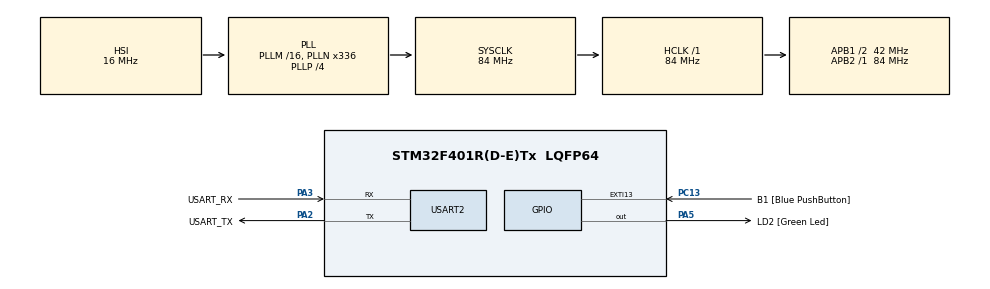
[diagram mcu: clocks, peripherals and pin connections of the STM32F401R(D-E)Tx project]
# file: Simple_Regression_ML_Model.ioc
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Mcu.Family=STM32F4
PA2.GPIO_PuPd=GPIO_NOPULL
VP_STMicroelectronics.X-CUBE-AI_VS_ArtificialOoIntelligenceJjXAaCUBEAaAI_6.0.0.Mode=ArtificialOoIntelligenceJjXAaCUBEAaAI
RCC.CortexFreq_Value=84000000
STMicroelectronics.X-CUBE-AI.6.0.0.ModelFlashOccupation-a35f5c20a5aa916bef2a292ab1ee2da6ee86460b59aac95d9a262698d66ec36b=16
STMicroelectronics.X-CUBE-AI.6.0.0.MaximumSizeOfInputLayer=AI_NETWORK_IN_1_SIZE_BYTES
PA14.GPIO_Label=TCK
VP_STMicroelectronics.X-CUBE-AI_VS_DeviceJjApplication_6.0.0.Mode=DeviceJjApplication
PA3.GPIO_PuPd=GPIO_NOPULL
PA2.GPIO_Speed=GPIO_SPEED_FREQ_LOW
STMicroelectronics.X-CUBE-AI.6.0.0.StackSize=0x1000
PA3.GPIO_Speed=GPIO_SPEED_FREQ_LOW
STMicroelectronics.X-CUBE-AI.6.0.0.ModelActualCompression-a35f5c20a5aa916bef2a292ab1ee2da6ee86460b59aac95d9a262698d66ec36b=0.0
RCC.SYSCLKSource=RCC_SYSCLKSOURCE_PLLCLK
ProjectManager.StackSize=0x1000
PH0\ -\ OSC_IN.Signal=RCC_OSC_IN
RCC.HCLKFreq_Value=84000000
RCC.APB2TimFreq_Value=84000000
RCC.AHBFreq_Value=84000000
STMicroelectronics.X-CUBE-AI.6.0.0.ModelCompression-a35f5c20a5aa916bef2a292ab1ee2da6ee86460b59aac95d9a262698d66ec36b=1
RCC.HSE_VALUE=8000000
PC13-ANTI_TAMP.Signal=GPXTI13
STMicroelectronics.X-CUBE-AI.6.0.0.XAaCUBEAaAICcArtificialOoIntelligenceJjCore=true
PA5.GPIO_PuPd=GPIO_NOPULL
NVIC.TIM2_IRQn=true\:0\:0\:false\:false\:true\:true\:true
STMicroelectronics.X-CUBE-AI.6.0.0.ModelMacc-a35f5c20a5aa916bef2a292ab1ee2da6ee86460b59aac95d9a262698d66ec36b=4
STMicroelectronics.X-CUBE-AI.6.0.0.ModelName-a35f5c20a5aa916bef2a292ab1ee2da6ee86460b59aac95d9a262698d66ec36b=network
Mcu.Package=LQFP64
TIM2.Prescaler=9999
USART2.VirtualMode=VM_ASYNC
PA2.GPIO_Label=USART_TX
RCC.APB1TimFreq_Value=84000000
STMicroelectronics.X-CUBE-AI.6.0.0.ModelStructureFile-a35f5c20a5aa916bef2a292ab1ee2da6ee86460b59aac95d9a262698d66ec36b=/Users/massimomerenda/eML/LARSEC/Regression_ML_Model/network_regression.h5
PA3.Signal=USART2_RX
STMicroelectronics.X-CUBE-AI.6.0.0.ModelRamOccupation-a35f5c20a5aa916bef2a292ab1ee2da6ee86460b59aac95d9a262698d66ec36b=16
PA2.GPIO_Mode=GPIO_MODE_AF_PP
PB3.GPIO_Label=SWO
PC13-ANTI_TAMP.GPIO_PuPd=GPIO_NOPULL
PC13-ANTI_TAMP.GPIO_Label=B1 [Blue PushButton]
STMicroelectronics.X-CUBE-AI.6.0.0.MaximumSizeOfOutputLayer=AI_NETWORK_OUT_1_SIZE_BYTES
RCC.APB1CLKDivider=RCC_HCLK_DIV2
PC14-OSC32_IN.Signal=RCC_OSC32_IN
PA3.Mode=Asynchronous
PA13.Signal=SYS_JTMS-SWDIO
STMicroelectronics.X-CUBE-AI.6.0.0.ModelHashList=a35f5c20a5aa916bef2a292ab1ee2da6ee86460b59aac95d9a262698d66ec36b
ProjectManager.TargetToolchain=STM32CubeIDE
STMicroelectronics.X-CUBE-AI.6.0.0.InternalRamActivationBufferMaxSize=AI_NETWORK_DATA_ACTIVATIONS_SIZE
PA3.GPIO_Mode=GPIO_MODE_AF_PP
STMicroelectronics.X-CUBE-AI.6.0.0.WorkingBufferStartAddrList=0xFFFFFFFF
STMicroelectronics.X-CUBE-AI.6.0.0.ModelNameList=network
STMicroelectronics.X-CUBE-AI.6.0.0.MaximumNumberOfOutputLayer=1
RCC.LSE_VALUE=32768
PC15-OSC32_OUT.Signal=RCC_OSC32_OUT
STMicroelectronics.X-CUBE-AI.6.0.0.LatestDirectoryUsed-a35f5c20a5aa916bef2a292ab1ee2da6ee86460b59aac95d9a262698d66ec36b=/Users/massimomerenda/eML/LARSEC/Regression_ML_Model
PA5.Signal=GPIO_Output
PH1\ -\ OSC_OUT.Signal=RCC_OSC_OUT
board=NUCLEO-F401RE
RCC.VCOOutputFreq_Value=336000000
RCC.APB2Freq_Value=84000000
VP_TIM2_VS_ClockSourceINT.Mode=Internal
STMicroelectronics.X-CUBE-AI.6.0.0.ModelKind-a35f5c20a5aa916bef2a292ab1ee2da6ee86460b59aac95d9a262698d66ec36b=KERAS
TIM2.Period=8399
STMicroelectronics.X-CUBE-AI.6.0.0.ApplicationCcDeviceJjApplication=ApplicationTemplate
Mcu.Name=STM32F401R(D-E)Tx
PA13.GPIO_Label=TMS
PA2.Signal=USART2_TX
PB3.Signal=SYS_JTDO-SWO
RCC.SYSCLKFreq_VALUE=84000000
PA5.GPIO_Label=LD2 [Green Led]
PC13-ANTI_TAMP.GPIO_ModeDefaultEXTI=GPIO_MODE_IT_FALLING
PA14.Signal=SYS_JTCK-SWCLK
STMicroelectronics.X-CUBE-AI.6.0.0.MaximumNumberOfInputLayer=1
ProjectManager.HeapSize=0x200
STMicroelectronics.X-CUBE-AI.6.0.0.HeapSize=0x200
RCC.HSI_VALUE=16000000
RCC.PLLP=RCC_PLLP_DIV4
PA5.GPIO_Speed=GPIO_SPEED_FREQ_LOW
RCC.PLLQ=7
NVIC.PriorityGroup=NVIC_PRIORITYGROUP_0
RCC.PLLN=336
PA2.Mode=Asynchronous
STMicroelectronics.X-CUBE-AI.6.0.0.ModelType-a35f5c20a5aa916bef2a292ab1ee2da6ee86460b59aac95d9a262698d66ec36b=Saved model
RCC.APB1Freq_Value=42000000
PA5.GPIO_Mode=GPIO_MODE_OUTPUT_PP
VP_CRC_VS_CRC.Mode=CRC_Activate
STMicroelectronics.X-CUBE-AI.6.0.0.ActivationBufferSizeList=16
PA3.GPIO_Label=USART_RX

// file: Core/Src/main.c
/* USER CODE BEGIN Header */
/**
  ******************************************************************************
  * @file           : main.c
  * @brief          : Main program body
  ******************************************************************************
  * @attention
  *
  * <h2><center>&copy; Copyright (c) 2021 STMicroelectronics.
  * All rights reserved.</center></h2>
  *
  * This software component is licensed by ST under BSD 3-Clause license,
  * the "License"; You may not use this file except in compliance with the
  * License. You may obtain a copy of the License at:
  *                        opensource.org/licenses/BSD-3-Clause
  *
  ******************************************************************************
  */
/* USER CODE END Header */
#include "main.h"
#include "app_x-cube-ai.h"

CRC_HandleTypeDef hcrc;

TIM_HandleTypeDef htim2;

UART_HandleTypeDef huart2;

void SystemClock_Config(void);
static void MX_GPIO_Init(void);
static void MX_CRC_Init(void);
static void MX_USART2_UART_Init(void);
static void MX_TIM2_Init(void);

int main(void)
{

  /* MCU Configuration--------------------------------------------------------*/

  /* Reset of all peripherals, Initializes the Flash interface and the Systick. */
  HAL_Init();

  /* Configure the system clock */
  SystemClock_Config();

  /* Initialize all configured peripherals */
  MX_GPIO_Init();
  MX_CRC_Init();
  MX_USART2_UART_Init();
  MX_TIM2_Init();
  MX_X_CUBE_AI_Init();
  /* USER CODE BEGIN 2 */

  HAL_TIM_Base_Start_IT(&htim2); // Timer 2 start command
  /* USER CODE END 2 */

  /* Infinite loop */
  while (1)
  {

  //MX_X_CUBE_AI_Process();
  }
}

void SystemClock_Config(void)
{
  RCC_OscInitTypeDef RCC_OscInitStruct = {0};
  RCC_ClkInitTypeDef RCC_ClkInitStruct = {0};

  /** Configure the main internal regulator output voltage
  */
  __HAL_RCC_PWR_CLK_ENABLE();
  __HAL_PWR_VOLTAGESCALING_CONFIG(PWR_REGULATOR_VOLTAGE_SCALE2);
  /** Initializes the RCC Oscillators according to the specified parameters
  * in the RCC_OscInitTypeDef structure.
  */
  RCC_OscInitStruct.OscillatorType = RCC_OSCILLATORTYPE_HSI;
  RCC_OscInitStruct.HSIState = RCC_HSI_ON;
  RCC_OscInitStruct.HSICalibrationValue = RCC_HSICALIBRATION_DEFAULT;
  RCC_OscInitStruct.PLL.PLLState = RCC_PLL_ON;
  RCC_OscInitStruct.PLL.PLLSource = RCC_PLLSOURCE_HSI;
  RCC_OscInitStruct.PLL.PLLM = 16;
  RCC_OscInitStruct.PLL.PLLN = 336;
  RCC_OscInitStruct.PLL.PLLP = RCC_PLLP_DIV4;
  RCC_OscInitStruct.PLL.PLLQ = 7;
  if (HAL_RCC_OscConfig(&RCC_OscInitStruct) != HAL_OK)
  {
    Error_Handler();
  }
  /** Initializes the CPU, AHB and APB buses clocks
  */
  RCC_ClkInitStruct.ClockType = RCC_CLOCKTYPE_HCLK|RCC_CLOCKTYPE_SYSCLK
                              |RCC_CLOCKTYPE_PCLK1|RCC_CLOCKTYPE_PCLK2;
  RCC_ClkInitStruct.SYSCLKSource = RCC_SYSCLKSOURCE_PLLCLK;
  RCC_ClkInitStruct.AHBCLKDivider = RCC_SYSCLK_DIV1;
  RCC_ClkInitStruct.APB1CLKDivider = RCC_HCLK_DIV2;
  RCC_ClkInitStruct.APB2CLKDivider = RCC_HCLK_DIV1;

  if (HAL_RCC_ClockConfig(&RCC_ClkInitStruct, FLASH_LATENCY_2) != HAL_OK)
  {
    Error_Handler();
  }
}

static void MX_CRC_Init(void)
{

  hcrc.Instance = CRC;
  if (HAL_CRC_Init(&hcrc) != HAL_OK)
  {
    Error_Handler();
  }

}

static void MX_TIM2_Init(void)
{

  TIM_ClockConfigTypeDef sClockSourceConfig = {0};
  TIM_MasterConfigTypeDef sMasterConfig = {0};

  htim2.Instance = TIM2;
  htim2.Init.Prescaler = 9999;
  htim2.Init.CounterMode = TIM_COUNTERMODE_UP;
  htim2.Init.Period = 8399;
  htim2.Init.ClockDivision = TIM_CLOCKDIVISION_DIV1;
  htim2.Init.AutoReloadPreload = TIM_AUTORELOAD_PRELOAD_DISABLE;
  if (HAL_TIM_Base_Init(&htim2) != HAL_OK)
  {
    Error_Handler();
  }
  sClockSourceConfig.ClockSource = TIM_CLOCKSOURCE_INTERNAL;
  if (HAL_TIM_ConfigClockSource(&htim2, &sClockSourceConfig) != HAL_OK)
  {
    Error_Handler();
  }
  sMasterConfig.MasterOutputTrigger = TIM_TRGO_RESET;
  sMasterConfig.MasterSlaveMode = TIM_MASTERSLAVEMODE_DISABLE;
  if (HAL_TIMEx_MasterConfigSynchronization(&htim2, &sMasterConfig) != HAL_OK)
  {
    Error_Handler();
  }

}

static void MX_USART2_UART_Init(void)
{

  huart2.Instance = USART2;
  huart2.Init.BaudRate = 115200;
  huart2.Init.WordLength = UART_WORDLENGTH_8B;
  huart2.Init.StopBits = UART_STOPBITS_1;
  huart2.Init.Parity = UART_PARITY_NONE;
  huart2.Init.Mode = UART_MODE_TX_RX;
  huart2.Init.HwFlowCtl = UART_HWCONTROL_NONE;
  huart2.Init.OverSampling = UART_OVERSAMPLING_16;
  if (HAL_UART_Init(&huart2) != HAL_OK)
  {
    Error_Handler();
  }

}

static void MX_GPIO_Init(void)
{
  GPIO_InitTypeDef GPIO_InitStruct = {0};

  /* GPIO Ports Clock Enable */
  __HAL_RCC_GPIOC_CLK_ENABLE();
  __HAL_RCC_GPIOH_CLK_ENABLE();
  __HAL_RCC_GPIOA_CLK_ENABLE();
  __HAL_RCC_GPIOB_CLK_ENABLE();

  /*Configure GPIO pin Output Level */
  HAL_GPIO_WritePin(LD2_GPIO_Port, LD2_Pin, GPIO_PIN_RESET);

  /*Configure GPIO pin : B1_Pin */
  GPIO_InitStruct.Pin = B1_Pin;
  GPIO_InitStruct.Mode = GPIO_MODE_IT_FALLING;
  GPIO_InitStruct.Pull = GPIO_NOPULL;
  HAL_GPIO_Init(B1_GPIO_Port, &GPIO_InitStruct);

  /*Configure GPIO pin : LD2_Pin */
  GPIO_InitStruct.Pin = LD2_Pin;
  GPIO_InitStruct.Mode = GPIO_MODE_OUTPUT_PP;
  GPIO_InitStruct.Pull = GPIO_NOPULL;
  GPIO_InitStruct.Speed = GPIO_SPEED_FREQ_LOW;
  HAL_GPIO_Init(LD2_GPIO_Port, &GPIO_InitStruct);

}

void Error_Handler(void)
{
  __disable_irq();
  while (1)
  {
  }
}

/************************ (C) COPYRIGHT STMicroelectronics *****END OF FILE****/
